# ADUC7023 register map
File version: 1.0
Registers are 32-bit, read-write, reset 0x0 unless marked. A register's access mark holds for its fields unless they carry their own. Offsets are from the block's base; [hi:lo] are bit positions; {n}, {i} and the like mark numbered series.

## GPIO — GENERAL-PURPOSE INPUT/OUTPUT
Base 0xFFFFF400
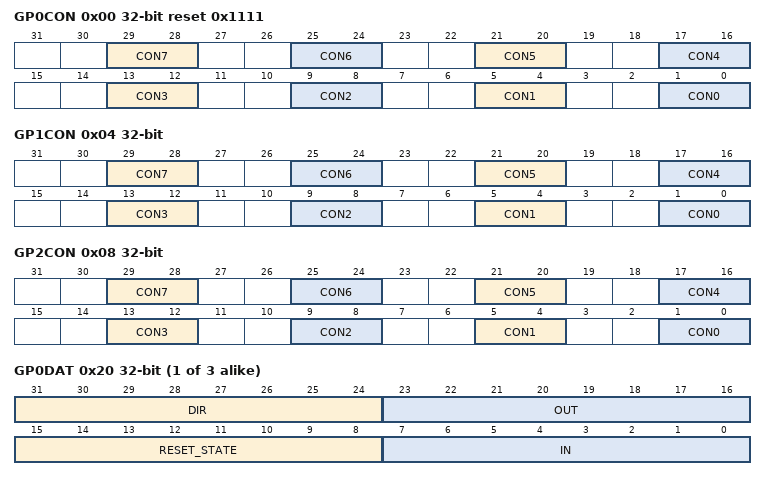
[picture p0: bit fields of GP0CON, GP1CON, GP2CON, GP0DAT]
0x00 GP0CON reset 0x1111 — GPIO Port0 control register
  [29:28] CON7 — Select function of P0.7 pin
  [25:24] CON6 — Select function of P0.6 pin
  [21:20] CON5 — Select function of P0.5 pin
  [17:16] CON4 — Select function of P0.4 pin
  [13:12] CON3 — Select function of P0.3 pin
  [9:8] CON2 — Select function of P0.2 pin
  [5:4] CON1 — Select function of P0.1 pin
  [1:0] CON0 — Select function of P0.0 pin
0x04 GP1CON — GPIO Port1 control register
  [29:28] CON7 — Select function of P1.7 pin
  [25:24] CON6 — Select function of P1.6 pin
  [21:20] CON5 — Select function of P1.5 pin
  [17:16] CON4 — Select function of P1.4 pin
  [13:12] CON3 — Select function of P1.3 pin
  [9:8] CON2 — Select function of P1.2 pin
  [5:4] CON1 — Select function of P1.1 pin
  [1:0] CON0 — Select function of P1.0 pin
0x08 GP2CON — GPIO Port2 control register
  [29:28] CON7 — Select function of P2.7 pin
  [25:24] CON6 — Select function of P2.6 pin
  [21:20] CON5 — Select function of P2.5 pin
  [17:16] CON4 — Select function of P2.4 pin
  [13:12] CON3 — Select function of P2.3 pin
  [9:8] CON2 — Select function of P2.2 pin
  [5:4] CON1 — Select function of P2.1 pin
  [1:0] CON0 — Select function of P2.0 pin
{0x20+0x10*i} GP{i}DAT (i=0..2) — GPIO Port{i} data control register
  [31:24] DIR — Direction of the data
  [23:16] OUT — Port data output
  [15:8] RESET_STATE ro — Reflect the state of Port pins at reset
  [7:0] IN ro — Port data input
{0x24+0x10*i} GP{i}SET wo (i=0..2) — GPIO Port{i} data set register
  [23:16] SET — Data port set bit
{0x28+0x10*i} GP{i}CLR wo (i=0..2) — GPIO Port{i} data clear register
  [23:16] CLR — Data port clear bit
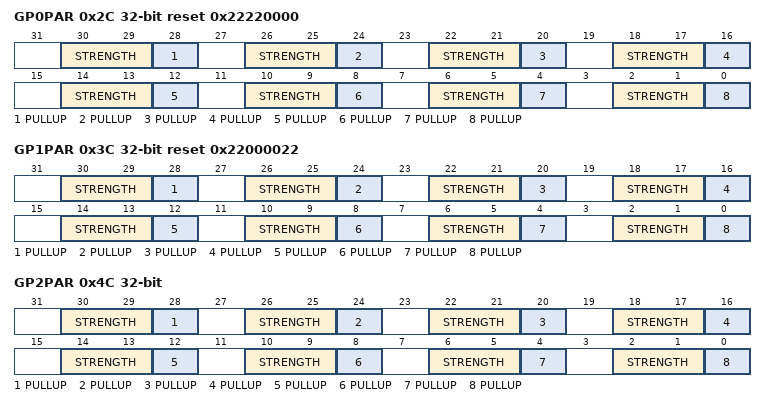
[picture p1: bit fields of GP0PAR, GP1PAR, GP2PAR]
0x2C GP0PAR reset 0x22220000 — GPIO Port0 pull-up disable register
  [30:29] STRENGTH — Drive strength P0.7 bit
  [28] PULLUP — Pull-up disable P0.7 bit
  [26:25] STRENGTH — Drive strength P0.6 bit
  [24] PULLUP — Pull-up disable P0.6 bit
  [22:21] STRENGTH — Drive strength P0.5 bit
  [20] PULLUP — Pull-up disable P0.5 bit
  [18:17] STRENGTH — Drive strength P0.4 bit
  [16] PULLUP — Pull-up disable P0.4 bit
  [14:13] STRENGTH — Drive strength P0.3 bit
  [12] PULLUP — Pull-up disable P0.3 bit
  [10:9] STRENGTH — Drive strength P0.2 bit
  [8] PULLUP — Pull-up disable P0.2 bit
  [6:5] STRENGTH — Drive strength P0.1 bit
  [4] PULLUP — Pull-up disable P0.1 bit
  [2:1] STRENGTH — Drive strength P0.0 bit
  [0] PULLUP — Pull-up disable P0.0 bit
0x3C GP1PAR reset 0x22000022 — GPIO Port1 pull-up disable register
  [30:29] STRENGTH — Drive strength P1.7 bit
  [28] PULLUP — Pull-up disable P1.7 bit
  [26:25] STRENGTH — Drive strength P1.6 bit
  [24] PULLUP — Pull-up disable P1.6 bit
  [22:21] STRENGTH — Drive strength P1.5 bit
  [20] PULLUP — Pull-up disable P1.5 bit
  [18:17] STRENGTH — Drive strength P1.4 bit
  [16] PULLUP — Pull-up disable P1.4 bit
  [14:13] STRENGTH — Drive strength P1.3 bit
  [12] PULLUP — Pull-up disable P1.3 bit
  [10:9] STRENGTH — Drive strength P1.2 bit
  [8] PULLUP — Pull-up disable P1.2 bit
  [6:5] STRENGTH — Drive strength P1.1 bit
  [4] PULLUP — Pull-up disable P1.1 bit
  [2:1] STRENGTH — Drive strength P1.0 bit
  [0] PULLUP — Pull-up disable P1.0 bit
0x4C GP2PAR — GPIO Port2 pull-up disable register
  [30:29] STRENGTH — Drive strength P2.7 bit
  [28] PULLUP — Pull-up disable P2.7 bit
  [26:25] STRENGTH — Drive strength P2.6 bit
  [24] PULLUP — Pull-up disable P2.6 bit
  [22:21] STRENGTH — Drive strength P2.5 bit
  [20] PULLUP — Pull-up disable P2.5 bit
  [18:17] STRENGTH — Drive strength P2.4 bit
  [16] PULLUP — Pull-up disable P2.4 bit
  [14:13] STRENGTH — Drive strength P2.3 bit
  [12] PULLUP — Pull-up disable P2.3 bit
  [10:9] STRENGTH — Drive strength P2.2 bit
  [8] PULLUP — Pull-up disable P2.2 bit
  [6:5] STRENGTH — Drive strength P2.1 bit
  [4] PULLUP — Pull-up disable P2.1 bit
  [2:1] STRENGTH — Drive strength P2.0 bit
  [0] PULLUP — Pull-up disable P2.0 bit
